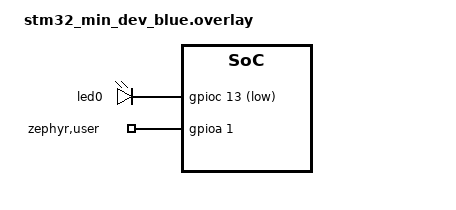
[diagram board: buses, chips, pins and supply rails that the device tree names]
/ {
    // LED da BLuepill
    leds {
        compatible = "gpio-leds";
        led0: led {
            gpios = <&gpioc 13 GPIO_ACTIVE_LOW>;
        };
    };

    zephyr,user {
       gpios = <&gpioa 1 GPIO_ACTIVE_HIGH>; // Onewire
    };

    aliases {
    };
};

/* vim: set filetype=dts : */
